AUTOSAR XML (schema 00044)
package /E40_Platform_System_SystemPackage/Components
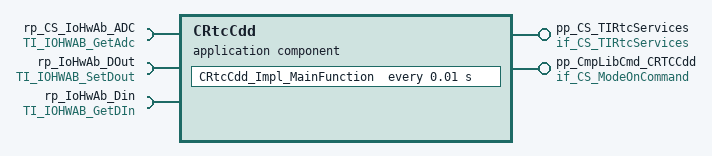
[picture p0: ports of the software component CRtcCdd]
  application sw component type CRtcCdd
    provide port pp_CS_TIRtcServices: provided-interface=if_CS_TIRtcServices
      provided-com-specs:
        operation=RtcCdd_ClearAlarm, queue-length=1
        operation=RtcCdd_GetTime, queue-length=1
        operation=RtcCdd_SetAlarm, queue-length=1
        operation=RtcCdd_SetTime, queue-length=1
    provide port pp_CmpLibCmd_CRTCCdd: server-com-spec{operation=Impl_OnCommand, queue-length=1}, provided-interface=if_CS_ModeOnCommand
    require port rp_CS_IoHwAb_ADC: required-com-specs=[GetAsyncRawAdc, GetProcessedAdc, GetSyncRawAdc], required-interface=TI_IOHWAB_GetAdc
    require port rp_IoHwAb_DOut: required-com-specs=[SetOutputGroup, SetOutputPin], required-interface=TI_IOHWAB_SetDout
    require port rp_IoHwAb_Din: required-com-specs=[GetAsyncRawInput, GetInputGroup, GetProcessedInput, GetSyncRawInput], required-interface=TI_IOHWAB_GetDIn
    behavior IB_CRtcCdd
      timing event TECRtcCdd_Impl_MainFunction: start-on-event=CRtcCdd_Impl_MainFunction, period=0.01
      5 x operation invoked event:
        OIE_pp_CmpLibCmd_CRTCCdd_CRtcCdd_Impl_OnCommandTrigByImpl_OnCommand: start-on-event=CRtcCdd_Impl_OnCommand, operation=pp_CmpLibCmd_CRTCCdd.Impl_OnCommand
        OIE_pp_CS_TIRtcServices_RtcCdd_ClearAlarmTrigByRtcCdd_ClearAlarm: start-on-event=RtcCdd_ClearAlarm, operation=pp_CS_TIRtcServices.RtcCdd_ClearAlarm
        OIE_pp_CS_TIRtcServices_RtcCdd_GetTimeTrigByRtcCdd_GetTime: start-on-event=RtcCdd_GetTime, operation=pp_CS_TIRtcServices.RtcCdd_GetTime
        OIE_pp_CS_TIRtcServices_RtcCdd_SetAlarmTrigByRtcCdd_SetAlarm: start-on-event=RtcCdd_SetAlarm, operation=pp_CS_TIRtcServices.RtcCdd_SetAlarm
        OIE_pp_CS_TIRtcServices_RtcCdd_SetTimeTrigByRtcCdd_SetTime: start-on-event=RtcCdd_SetTime, operation=pp_CS_TIRtcServices.RtcCdd_SetTime
      port-api-options:
        enable-take-address=false, indirect-api=false, port=pp_CS_TIRtcServices
        enable-take-address=false, indirect-api=false, port=pp_CmpLibCmd_CRTCCdd
        enable-take-address=false, indirect-api=false, port=rp_CS_IoHwAb_ADC
        enable-take-address=false, indirect-api=false, port=rp_IoHwAb_DOut
        enable-take-address=false, indirect-api=false, port=rp_IoHwAb_Din
      6 x runnable, all with can-be-invoked-concurrently=true:
        CRtcCdd_Impl_MainFunction
          9 x sync call:
            OA_rp_CS_IoHwAb_ADC_GetAsyncRawAdc: operation=rp_CS_IoHwAb_ADC.GetAsyncRawAdc
            OA_rp_CS_IoHwAb_ADC_GetSyncRawAdc: operation=rp_CS_IoHwAb_ADC.GetSyncRawAdc
            OA_rp_CS_IoHwAb_ADC_GetProcessedAdc: operation=rp_CS_IoHwAb_ADC.GetProcessedAdc
            OA_rp_IoHwAb_DOut_SetOutputGroup: operation=rp_IoHwAb_DOut.SetOutputGroup
            OA_rp_IoHwAb_DOut_SetOutputPin: operation=rp_IoHwAb_DOut.SetOutputPin
            OA_rp_IoHwAb_Din_GetAsyncRawInput: operation=rp_IoHwAb_Din.GetAsyncRawInput
            OA_rp_IoHwAb_Din_GetProcessedInput: operation=rp_IoHwAb_Din.GetProcessedInput
            OA_rp_IoHwAb_Din_GetSyncRawInput: operation=rp_IoHwAb_Din.GetSyncRawInput
            OA_rp_IoHwAb_Din_GetInputGroup: operation=rp_IoHwAb_Din.GetInputGroup
        CRtcCdd_Impl_OnCommand
        RtcCdd_ClearAlarm
        RtcCdd_GetTime
        RtcCdd_SetAlarm
        RtcCdd_SetTime
  swc implementation IMPL_CRtcCdd: behavior=IB_CRtcCdd
